# TPTC0 register map
Vendor: Texas Instruments
Peripheral module from a debugger description file (folder omap4430).
Registers are 32-bit, read-only, reset 0x0 unless marked. A register's access mark holds for its fields unless they carry their own. Offsets are as the file gives them; lines under a group give offsets from that group; [hi:lo] are bit positions; {n}, {i} and the like mark numbered series; 'fields as' and 'values as' point back to an identical list; <NAME> marks a mode.

## TPTC0
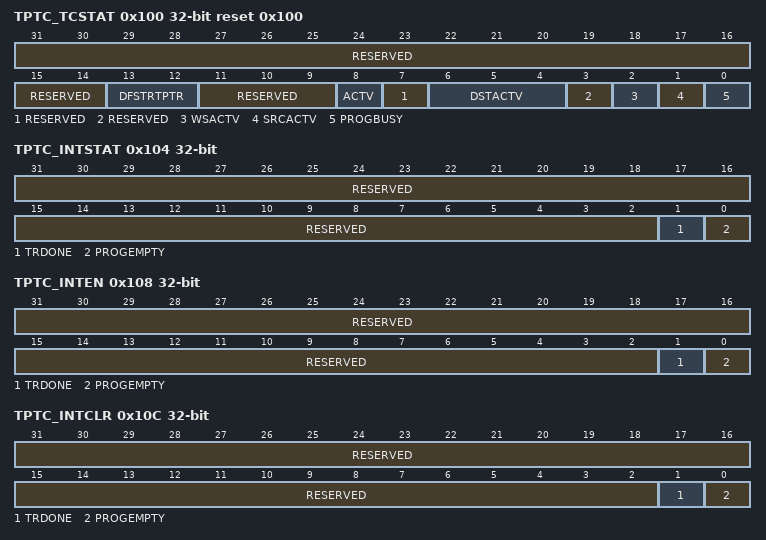
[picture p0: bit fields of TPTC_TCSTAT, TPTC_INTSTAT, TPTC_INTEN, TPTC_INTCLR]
0x100 TPTC_TCSTAT reset 0x100 — TC Status Register
  [31:14] RESERVED — reads return 0's
  [13:12] DFSTRTPTR — Dst FIFO Start Pointer Represents the offset to the head entry of Dst Register FIFO, in units of *entries*.Legal values = 0x0 to 0x3
  [11:9] RESERVED — reads return 0's
  [8] ACTV — Channel Active Channel Active is a logical-OR of each of the *BUSY/ACTV signals. The ACTV bit must remain high through the life of a TR.0 : Channel is idle.1 : Channel is busy.
  [7] RESERVED — reads return 0's
  [6:4] DSTACTV — Destination Active State Specifies the number of TRs that are resident in the Dst Register FIFO at a given instant. Legal values are constrained by the DSTREGDEPTH parameter.
    0=DSTACTV_0_r (FIFO set is empty.); {v}=DSTACTV_{v}_r (Dst FIFO contains {v} TR) (v=1..4)
  [3] RESERVED — reads return 0's
  [2] WSACTV — Write Status Active0 : Write status is not pending. Write status has been received for all previously issued write commands.1 : Write Status is pending. Write status has not been received for all previously issued write commands.
  [1] SRCACTV — Source Active State0 : Source Active set is idle. Any TR written to Prog Set will immediately transition to Source Active set as long as the Dst FIFO Set is not full (DSTFULL == 1).1 : Source Active set is busy either performing read transfers or waiting to perform read transfers for current Transfer Request.
  [0] PROGBUSY — Program Register Set Busy0 : Prog set idle and is available for programming.1 : Prog set busy.User should poll for PROGBUSY equal to 0 prior to re-programming the Program Register set.
0x104 TPTC_INTSTAT — Interrupt Status Register
  [31:2] RESERVED — reads return 0's
  [1] TRDONE — TR Done Event Status:0 : Condition not detected.1 : Set when TC has completed a Transfer Request.TRDONE should be set when the write status is returned for the final write of a TR.Cleared when write 1
  [0] PROGEMPTY — Program Set Empty Event Status:PROGEMPTY = 0 : Condition not detected.PROGEMPTY = 1 : Set when Program Register set transitions to empty state.Cleared when write 1
0x108 TPTC_INTEN rw — Interrupt Enable Register
  [31:2] RESERVED — write 0's for future compatibility reads return 0's
  [1] TRDONE — TR Done Event Enable:0 : disabled.1 : enabled, and contributes to interrupt generation
  [0] PROGEMPTY — Program Set Empty Event Enable:0 : PROGEMPTY Event is disabled.1 : PROGEMPTY Event is enabled, and contributes to interrupt generation
0x10C TPTC_INTCLR wo — Interrupt Clear Register
  [31:2] RESERVED — write 0's for future compatibility
  [1] TRDONE — TR Done Event Clear:0 : no effect.1 : clears TRDONE bit
  [0] PROGEMPTY — Program Set Empty Event Clear:0 : no effect.1 : clears PROGEMPTY bit
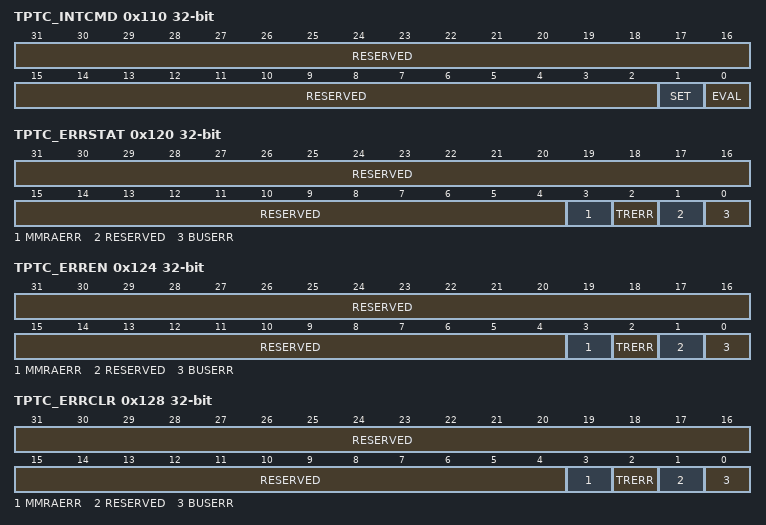
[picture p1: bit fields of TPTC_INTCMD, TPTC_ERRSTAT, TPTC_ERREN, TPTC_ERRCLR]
0x110 TPTC_INTCMD wo — Interrupt Command Register
  [31:2] RESERVED — write 0's for future compatibility
  [1] SET — Set TPTC interrupt:Write 1: causes TPTC interrupt to be pulsed unconditionally.Write 0: no affect.
  [0] EVAL — Evaluate state of TPTC interruptWrite 1 causes TPTC interrupt to be pulsed if any of the TPTC_INTSTAT bits are set to 1.Write 0: no affect.
0x120 TPTC_ERRSTAT — Error Status Register
  [31:4] RESERVED — reads return 0's
  [3] MMRAERR — MMR Address Error:0 : Condition not detected.1 : User attempted to read or write to invalid address configuration memory map.No additional error information is recorded.
  [2] TRERR — TR Error:TR detected that violates FIFO Mode transfer (SAM or DAM is 1) alignment rules or has ACNT or BCNT == 0. No additional error information is recorded.
  [1] RESERVED — reads return 0's
  [0] BUSERR — Bus Error Event:0: Condition not detected.1: TC has detected an error code on the write response bus or read response bus.Error information is stored in Error Details Register (TPTC_ERRDET).
0x124 TPTC_ERREN access per field — Error Enable Register
  [31:4] RESERVED ro — write 0's for future compatibility reads return 0's
  [3] MMRAERR rw — Interrupt enable MMRAERR:0: disabled.1: enabled, and contributes to the TPTC error interrupt generation.
  [2] TRERR rw — Interrupt enable for TRERR:0: disabled.1: enabled, and contributes to the TPTC error interrupt generation.
  [1] RESERVED rw — write 0's for future compatibility reads return 0's
  [0] BUSERR rw — Interrupt enable for BUSERR:0: disabled.1: enabled, and contributes to the TPTC error interrupt generation.
0x128 TPTC_ERRCLR wo — Error Clear Register
  [31:4] RESERVED — write 0's for future compatibility
  [3] MMRAERR — Interrupt clear for MMRAERR:Write 0 : no effect.Write 1: clears MMRAERR bit. This does not clear the TPTC_ERRDET register.
  [2] TRERR — Interrupt clear for TRERR:Writes 0: no effect.Write of 1: clears TRERR bit. This does not clear the ERRDET register.
  [1] RESERVED — write 0's for future compatibility
  [0] BUSERR — Interrupt clear for BUSERR:Writes 0: no effect.Write 1: clears BUSERR bit. This does not clear the ERRDET register.
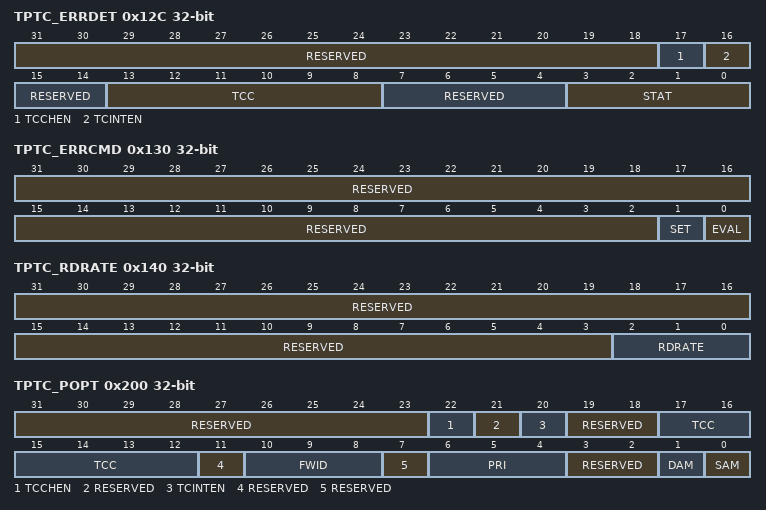
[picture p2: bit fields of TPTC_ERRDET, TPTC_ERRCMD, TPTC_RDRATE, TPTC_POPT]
0x12C TPTC_ERRDET — Error Details Register
  [31:18] RESERVED — reads return 0's
  [17] TCCHEN — Contains the OPT.TCCHEN value programmed by the user for the Read or Write transaction that resulted in an error.
  [16] TCINTEN — Contains the OPT.TCINTEN value programmed by the user for the Read or Write transaction that resulted in an error.
  [15:14] RESERVED — reads return 0's
  [13:8] TCC — Transfer Complete Code:Contains the OPT.TCC value programmed by the user for the Read or Write transaction that resulted in an error.
  [7:4] RESERVED — reads return 0's
  [3:0] STAT — Transaction Status:Stores the non-zero status/error code that was detected on the read status or write status bus. MS-bit effectively serves as the read vs. write error code. If read status and write status are returned on the same cycle, then the TC chooses non-zero version. If both are non-zero then write status is treated as higher priority.
    0=STAT_0_r (No Error (should not cause error to be latched)); 1=STAT_1_r (Read Addressing error); 2=STAT_2_r (Read Privilege error); 3=STAT_3_r (Read Timeout error); 4=STAT_4_r (Read Data error); 7=STAT_7_r (Read Exclusive-operation failure); 8=STAT_8_r (No Error (should not cause error to be latched)); 9=STAT_9_r (Write Addressing error); 10=STAT_10_r (Write Privilege error); 11=STAT_11_r (Write Timeout error); 12=STAT_12_r (Write Data error); 15=STAT_15_r (Write Exclusive-operation failure)
0x130 TPTC_ERRCMD wo — Error Command Register
  [31:2] RESERVED — write 0's for future compatibility
  [1] SET — Set TPTC error interrupt:Write 1: cause TPTC error interrupt to be pulsed unconditionally.Write 0: no affect.
  [0] EVAL — Evaluate state of TPTC error interruptWrite 1: cause TPTC error interrupt to be pulsed if any of the TPTC_ERRSTAT bits are set to 1.Write 0: no affect.
0x140 TPTC_RDRATE rw — Read Rate Register
  [31:3] RESERVED — write 0's for future compatibility reads return 0's
  [2:0] RDRATE — Read Rate Control:Controls the number of cycles between read commands. This is a global setting that applies to all TRs for this TC.
    0=Reads issued as fast as possible; 1=4 cycles between reads; 2=8 cycles between reads; 3=16 cycles between reads; 4=32 cycles between reads
0x200 TPTC_POPT rw — Prog Set Options
  [31:23] RESERVED — write 0's for future compatibility reads return 0's
  [22] TCCHEN — Transfer complete chaining enable:0: disabled.1: enabled.
  [21] RESERVED — write 0's for future compatibility reads return 0's
  [20] TCINTEN — Transfer complete interrupt enable:0: disabled.1: enabled.
  [19:18] RESERVED — write 0's for future compatibility reads return 0's
  [17:12] TCC — Transfer Complete Code:The 6-bit code is used to set the relevant bit in CER or IPR of the TPCC module.
  [11] RESERVED — write 0's for future compatibility reads return 0's
  [10:8] FWID — FIFO width control:Applies if either SAM or DAM is set to FIFO mode.
    0=FIFO width is 8-bit; 1=FIFO width is 16-bit; 2=FIFO width is 32-bit; 3=FIFO width is 64-bit; 4=FIFO width is 128-bit; 5=FIFO width is 256-bit
  [7] RESERVED — write 0's for future compatibility reads return 0's
  [6:4] PRI — Transfer Priority:
    0=Priority 0 - Highest priority; {v}=Priority {v} (v=1..6); 7=Priority 7 - Lowest Priority
  [3:2] RESERVED — write 0's for future compatibility reads return 0's
  [1] DAM — Destination Address Mode within an array:0: INCR, Dst addressing within an array increments.1: FIFO, Dst addressing within an array wraps around upon reaching FIFO width.
  [0] SAM — Source Address Mode within an array:0: INCR, Src addressing within an array increments.1: FIFO, Src addressing within an array wraps around upon reaching FIFO width.
0x204 TPTC_PSRC rw — Prog Set Src Address
  [31:0] SADDR — Source address for Program Register Set
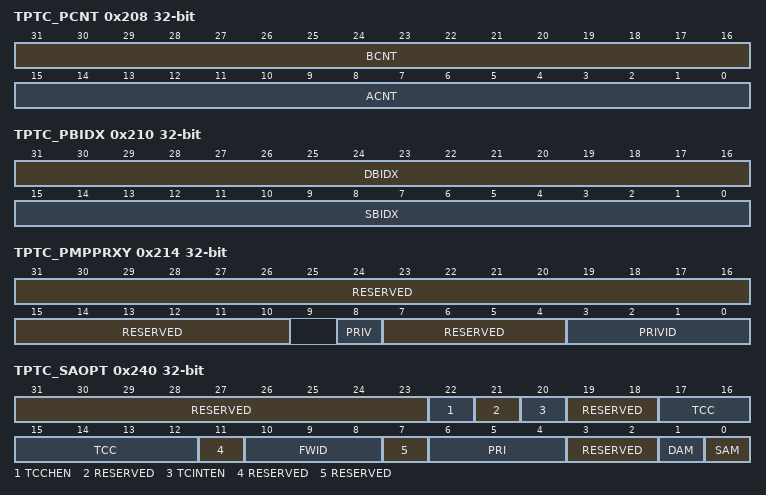
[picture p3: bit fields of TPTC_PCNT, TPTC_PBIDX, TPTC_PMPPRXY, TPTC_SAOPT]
0x208 TPTC_PCNT rw — Prog Set Count
  [31:16] BCNT — B-Dimension count.Number of arrays to be transferred, where each array is ACNT in length.
  [15:0] ACNT — A-Dimension count.Number of bytes to be transferred in first dimension.
0x20C TPTC_PDST rw — Prog Set Dst Address
  [31:0] DADDR — Destination address for Program Register Set
0x210 TPTC_PBIDX rw — Prog Set B-Dim Idx
  [31:16] DBIDX — B-Idx offset between Destination arrays:Represents the offset in bytes between the starting address of each destination array (recall that there are BCNT arrays of ACNT elements). DBIDX is always used, regardless of whether DAM is Increment or FIFO mode.
  [15:0] SBIDX — B-Idx offset between Source arrays:Represents the offset in bytes between the starting address of each source array (recall that there are BCNT arrays of ACNT elements). SBIDX is always used, regardless of whether SAM is Increment or FIFO mode.
0x214 TPTC_PMPPRXY — Prog Set Mem Protect Proxy
  [31:10] RESERVED — reads return 0's
  [8] PRIV — Privilege Level:0 : User level privilege1 : Supervisor level privilegePRIV is always updated with the value from the configuration bus privilege field on any/every write to Program Set BIDX Register (trigger register). The PRIV value for the SA Set and DF Set are copied from the value in the Program set along with the remainder of the parameter values. The privilege ID is issued on the VBusM read and write command bus such that the target endpoints can perform memory protection checks based on the PRIV of the external host that sets up the DMA transaction.
  [7:4] RESERVED — reads return 0's
  [3:0] PRIVID — Privilege ID:PRIVID is always updated with the value from configuration bus privilege ID field on any/every write to Program Set BIDX Register (trigger register). The PRIVID value for the SA Set and DF Set are copied from the value in the Program set along with the remainder of the parameter values. The privilege ID is issued on the VBusM read and write command bus such that the target endpoints can perform memory protection checks based on the privid of the external host that sets up the DMA transaction.
0x240 TPTC_SAOPT — Src Actv Set Options
  [31:23] RESERVED — reads return 0's
  [22] TCCHEN — Transfer complete chaining enable:0: disabled.1: enabled.
  [21] RESERVED — reads return 0's
  [20] TCINTEN — Transfer complete interrupt enable:0: disabled.1: enabled.
  [19:18] RESERVED — reads return 0's
  [17:12] TCC — Transfer Complete Code:The 6-bit code is used to set the relevant bit in CER or IPR of the TPCC module.
  [11] RESERVED — reads return 0's
  [10:8] FWID — FIFO width control: Applies if either SAM or DAM is set to FIFO mode.
    0=FWID_0_r (FIFO width is 8-bit); 1=FWID_1_r (FIFO width is 16-bit); 2=FWID_2_r (FIFO width is 32-bit); 3=FWID_3_r (FIFO width is 64-bit); 4=FWID_4_r (FIFO width is 128-bit); 5=FWID_5_r (FIFO width is 256-bit)
  [7] RESERVED — reads return 0's
  [6:4] PRI — Transfer Priority:
    0=PRI_0_r (Priority 0 - Highest priority); {v}=PRI_{v}_r (Priority {v}) (v=1..6); 7=PRI_7_r (Priority 7 - Lowest Priority)
  [3:2] RESERVED — reads return 0's
  [1] DAM — Destination Address Mode within an array:0: INCR, Dst addressing within an array increments.1: FIFO, Dst addressing within an array wraps around upon reaching FIFO width.
  [0] SAM — Source Address Mode within an array:0: INCR, Src addressing within an array increments.1: FIFO, Src addressing within an array wraps around upon reaching FIFO width.
0x244 TPTC_SASRC — Src Actv Set Src Address
  [31:0] SADDR — Source address for Source Active Register Set:Initial value is copied from PSRC.SADDR. TC updates value according to source addressing mode (OPT.SAM) and/or source index value (BIDX.SBIDX) after each read command is issued. When a TR is complete, the final value should be the address of the last read command issued.
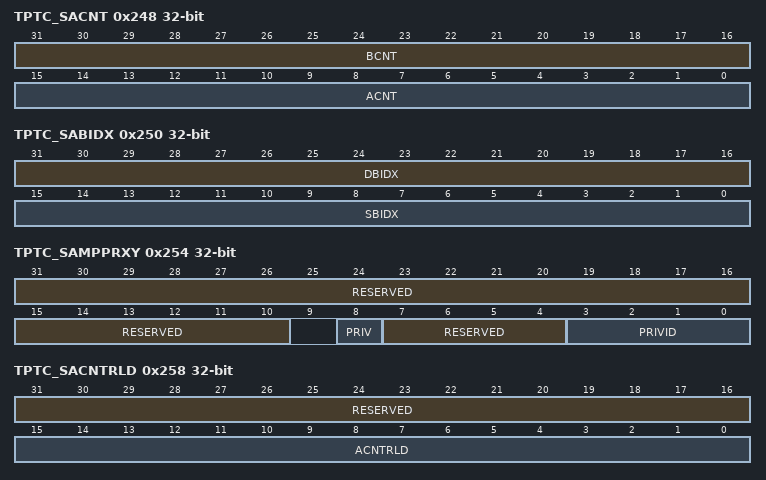
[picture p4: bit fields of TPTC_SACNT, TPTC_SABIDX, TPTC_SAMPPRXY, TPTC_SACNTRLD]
0x248 TPTC_SACNT — Src Actv Set Count
  [31:16] BCNT — B-Dimension count:Number of arrays to be transferred, where each array is ACNT in length. Count Remaining for Src Active Register Set. Represents the amount of data remaining to be read. Initial value is copied from PCNT. TC decrements ACNT and BCNT as necessary after each read command is issued. Final value should be 0 when TR is complete.
  [15:0] ACNT — A-Dimension count:Number of bytes to be transferred in first dimension. Count Remaining for Src Active Register Set. Represents the amount of data remaining to be read. Initial value is copied from PCNT. TC decrements ACNT and BCNT as necessary after each read command is issued. Final value should be 0 when TR is complete.
0x24C TPTC_SADST — return 0x0 w/o AERROR
  [31:0] DADDR — Destination address is not applicable for Src Active Register Set. Reads return 0x0
0x250 TPTC_SABIDX — Src Actv Set B-Dim Idx
  [31:16] DBIDX — Dest B-Idx for Source Active Register SetValue copied from PBIDX: B-Idx offset between Destination arrays: Represents the offset in bytes between the starting address of each destination array (recall that there are BCNT arrays of ACNT elements). DBIDX is always used, regardless of whether DAM is Increment or FIFO mode.
  [15:0] SBIDX — Source B-Idx for Source Active Register SetValue copied from PBIDX: B-Idx offset between Source arrays: Represents the offset in bytes between the starting address of each source array (recall that there are BCNT arrays of ACNT elements). SBIDX is always used, regardless of whether SAM is Increment or FIFO mode.
0x254 TPTC_SAMPPRXY — Src Actv Set Mem Protect Proxy
  [31:10] RESERVED — reads return 0's
  [8] PRIV — Privilege Level:0 : User level privilege1 : Supervisor level privilege PRIV is always updated with the value from the configuration bus privilege field on any/every write to Program Set BIDX Register (trigger register). The PRIV value for the SA Set and DF Set are copied from the value in the Program set along with the remainder of the parameter values. The privilege ID is issued on the VBusM read and write command bus such that the target endpoints can perform memory protection checks based on the PRIV of the external host that sets up the DMA transaction.
  [7:4] RESERVED — reads return 0's
  [3:0] PRIVID — Privilege ID:PRIVID is always updated with the value from configuration bus privilege ID field on any/every write to Program Set BIDX Register (trigger register). The PRIVID value for the SA Set and DF Set are copied from the value in the Program set along with the remainder of the parameter values. The privilege ID is issued on the VBusM read and write command bus such that the target endpoints can perform memory protection checks based on the privid of the external host that sets up the DMA transaction.
0x258 TPTC_SACNTRLD — Src Actv Set Cnt Reload
  [31:16] RESERVED — reads return 0's
  [15:0] ACNTRLD — A-Cnt Reload value for Source Active Register set.Value copied from PCNT.ACNT: Represents the originally programmed value of ACNT. The Reload value is used to reinitialize ACNT after each array is serviced (that is, ACNT decrements to 0). by the Src offset in bytes between the starting address of each source array (recall that there are BCNT arrays of ACNT bytes)
0x25C TPTC_SASRCBREF — Src Actv Set Src Addr A-Reference
  [31:0] SADDRBREF — Source address reference for Source Active Register Set:Represents the starting address for the array currently being read. The next array's starting address is calculated as the 'reference address' plus the 'source b-idx' value.
0x260 TPTC_SADSTBREF — return 0x0 w/o AERROR
  [31:0] DADDRBREF — Dst address reference is not applicable for Src Active Register Set. Reads return 0x0.
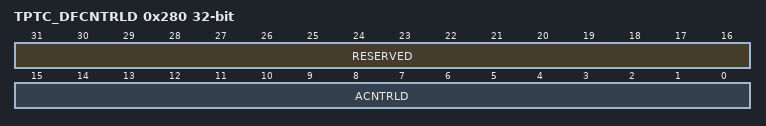
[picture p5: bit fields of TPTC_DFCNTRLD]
0x280 TPTC_DFCNTRLD — Dst FIFO Set Cnt Reload
  [31:16] RESERVED — reads return 0's
  [15:0] ACNTRLD — A-Cnt Reload value for Destination FIFO Register set.Value copied from PCNT.ACNT: Represents the originally programmed value of ACNT. The Reload value is used to reinitialize ACNT after each array is serviced (that is, ACNT decrements to 0). by the Src offset in bytes between the starting address of each source array (recall that there are BCNT arrays of ACNT bytes)
0x284 TPTC_DFSRCBREF — return 0x0 w/o AERROR
  [31:0] SADDRBREF — Source address reference is not applicable for Dst FIFO Register Set. Reads return 0x0.
0x288 TPTC_DFDSTBREF — Dst FIFO Set Dst Addr A-Reference
  [31:0] DADDRBREF — Destination address reference for Dst FIFO Register Set:Represents the starting address for the array currently being written. The next array's starting address is calculated as the 'reference address' plus the 'dest bidx' value.
